# AVR32DD20 register map
Vendor: Atmel; File version: 1.0
CPU: other r0p0, little endian, no MPU, no FPU, 4 interrupt priority bits
Registers are 8-bit, read-write, reset 0x0 unless marked. A register's access mark holds for its fields unless they carry their own. Offsets are from the block's base; [hi:lo] are bit positions.

## CPU
Base 0x00000034
0x00 CCP — Configuration Change Protection
  [7:0] CCP — CCP signature
    157=SPM (SPM Instruction Protection); 216=IOREG (IO Register Protection)

## CPUINT — Interrupt Controller
Base 0x00000110
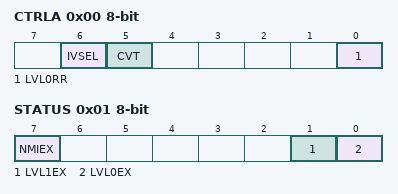
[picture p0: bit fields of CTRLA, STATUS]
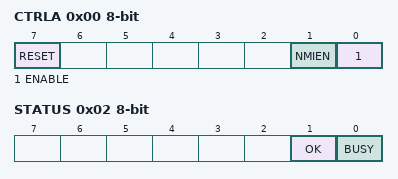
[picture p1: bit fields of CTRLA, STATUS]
0x00 CTRLA — Control A
  [6] IVSEL — Interrupt Vector Select
  [5] CVT — Compact Vector Table
  [0] LVL0RR — Round-robin Scheduling Enable
0x01 STATUS ro
  [7] NMIEX — Non-maskable Interrupt Executing
  [1] LVL1EX — Level 1 Interrupt Executing
  [0] LVL0EX — Level 0 Interrupt Executing
0x02 LVL0PRI — Interrupt Level 0 Priority
  [7:0] LVL0PRI — Interrupt Level Priority
0x03 LVL1VEC — Interrupt Level 1 Priority Vector
  [7:0] LVL1VEC — Interrupt Vector with High Priority

## CRCSCAN
Base 0x00000120
0x00 CTRLA — Control A
  [7] RESET — Reset CRC scan
  [1] NMIEN — Enable NMI Trigger
  [0] ENABLE — Enable CRC scan
0x01 CTRLB — Control B
  [1:0] SRC — CRC Source
    0=FLASH (CRC on entire flash); 1=APPLICATION (CRC on boot and appl section of flash); 2=BOOT (CRC on boot section of flash)
0x02 STATUS ro
  [1] OK — CRC Ok
  [0] BUSY — CRC Busy

## DAC0 — Digital to Analog Converter
Base 0x000006A0
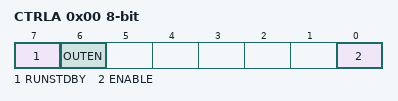
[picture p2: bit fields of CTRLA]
0x00 CTRLA — Control Register A
  [7] RUNSTDBY — Run in Standby Mode
  [6] OUTEN — Output Buffer Enable
  [0] ENABLE — DAC Enable
0x02 DATA 16-bit (reset mask 0xFF)
  [15:6] DATA

## FUSE — Fuses
Base 0x00001050
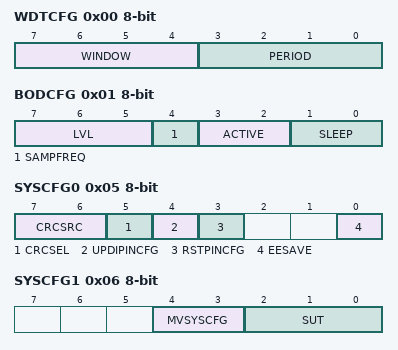
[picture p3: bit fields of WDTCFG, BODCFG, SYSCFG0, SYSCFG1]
0x00 WDTCFG — Watchdog Configuration
  [7:4] WINDOW — Watchdog Window Timeout Period
    0=OFF (Window mode off); 1=8CLK (8 cycles (8ms)); 2=16CLK (16 cycles (16ms)); 3=32CLK (32 cycles (32ms)); 4=64CLK (64 cycles (64ms)); 5=128CLK (128 cycles (0.128s)); 6=256CLK (256 cycles (0.256s)); 7=512CLK (512 cycles (0.512s)); 8=1KCLK (1K cycles (1.0s)); 9=2KCLK (2K cycles (2.0s)); 10=4KCLK (4K cycles (4.0s)); 11=8KCLK (8K cycles (8.0s))
  [3:0] PERIOD — Watchdog Timeout Period
    0=OFF (Watch-Dog timer Off); 1=8CLK (8 cycles (8ms)); 2=16CLK (16 cycles (16ms)); 3=32CLK (32 cycles (32ms)); 4=64CLK (64 cycles (64ms)); 5=128CLK (128 cycles (0.128s)); 6=256CLK (256 cycles (0.256s)); 7=512CLK (512 cycles (0.512s)); 8=1KCLK (1K cycles (1.0s)); 9=2KCLK (2K cycles (2.0s)); 10=4KCLK (4K cycles (4.0s)); 11=8KCLK (8K cycles (8.0s))
0x01 BODCFG — BOD Configuration
  [7:5] LVL — BOD Level
    0=BODLEVEL0 (1.9V); 1=BODLEVEL1 (2.45V); 2=BODLEVEL2 (2.7V); 3=BODLEVEL3 (2.85V)
  [4] SAMPFREQ — BOD Sample Frequency
    0=128Hz (Sample frequency is 128 Hz); 1=32Hz (Sample frequency is 32 Hz)
  [3:2] ACTIVE — BOD Operation in Active Mode
    0=DISABLE (BOD disabled); 1=ENABLE (BOD enabled in continuous mode); 2=SAMPLE (BOD enabled in sampled mode); 3=ENABLEWAIT (BOD enabled in continuous mode. Execution is halted at wake-up until BOD is running.)
  [1:0] SLEEP — BOD Operation in Sleep Mode
    0=DISABLE (BOD disabled); 1=ENABLE (BOD enabled in continuous mode); 2=SAMPLE (BOD enabled in sampled mode)
0x02 OSCCFG — Oscillator Configuration
  [2:0] CLKSEL — Frequency Select
    0=OSCHF (1-32MHz internal oscillator); 1=OSC32K (32.768kHz internal oscillator)
0x05 SYSCFG0 — System Configuration 0
  [7:6] CRCSRC — CRC Source
    0=FLASH (CRC of full Flash (boot, application code and application data)); 1=BOOT (CRC of boot section); 2=BOOTAPP (CRC of application code and boot sections); 3=NOCRC
  [5] CRCSEL — CRC Select
    0=CRC16 (Enable CRC16); 1=CRC32 (Enable CRC32)
  [4] UPDIPINCFG — UPDI Pin Configuration
    0=GPIO (GPIO Mode); 1=UPDI (UPDI Mode)
  [3] RSTPINCFG — Reset Pin Configuration
    0=GPIO (GPIO mode); 1=RST (Reset mode)
  [0] EESAVE — EEPROM Save
0x06 SYSCFG1 — System Configuration 1
  [4:3] MVSYSCFG — MVIO System Configuration
    1=DUAL (Device used in a dual supply configuration); 2=SINGLE (Device used in a single supply configuration)
  [2:0] SUT — Startup Time
    0=0MS; 1=1MS; 2=2MS; 3=4MS; 4=8MS; 5=16MS; 6=32MS; 7=64MS
0x07 CODESIZE — Code Section Size
0x08 BOOTSIZE — Boot Section Size
